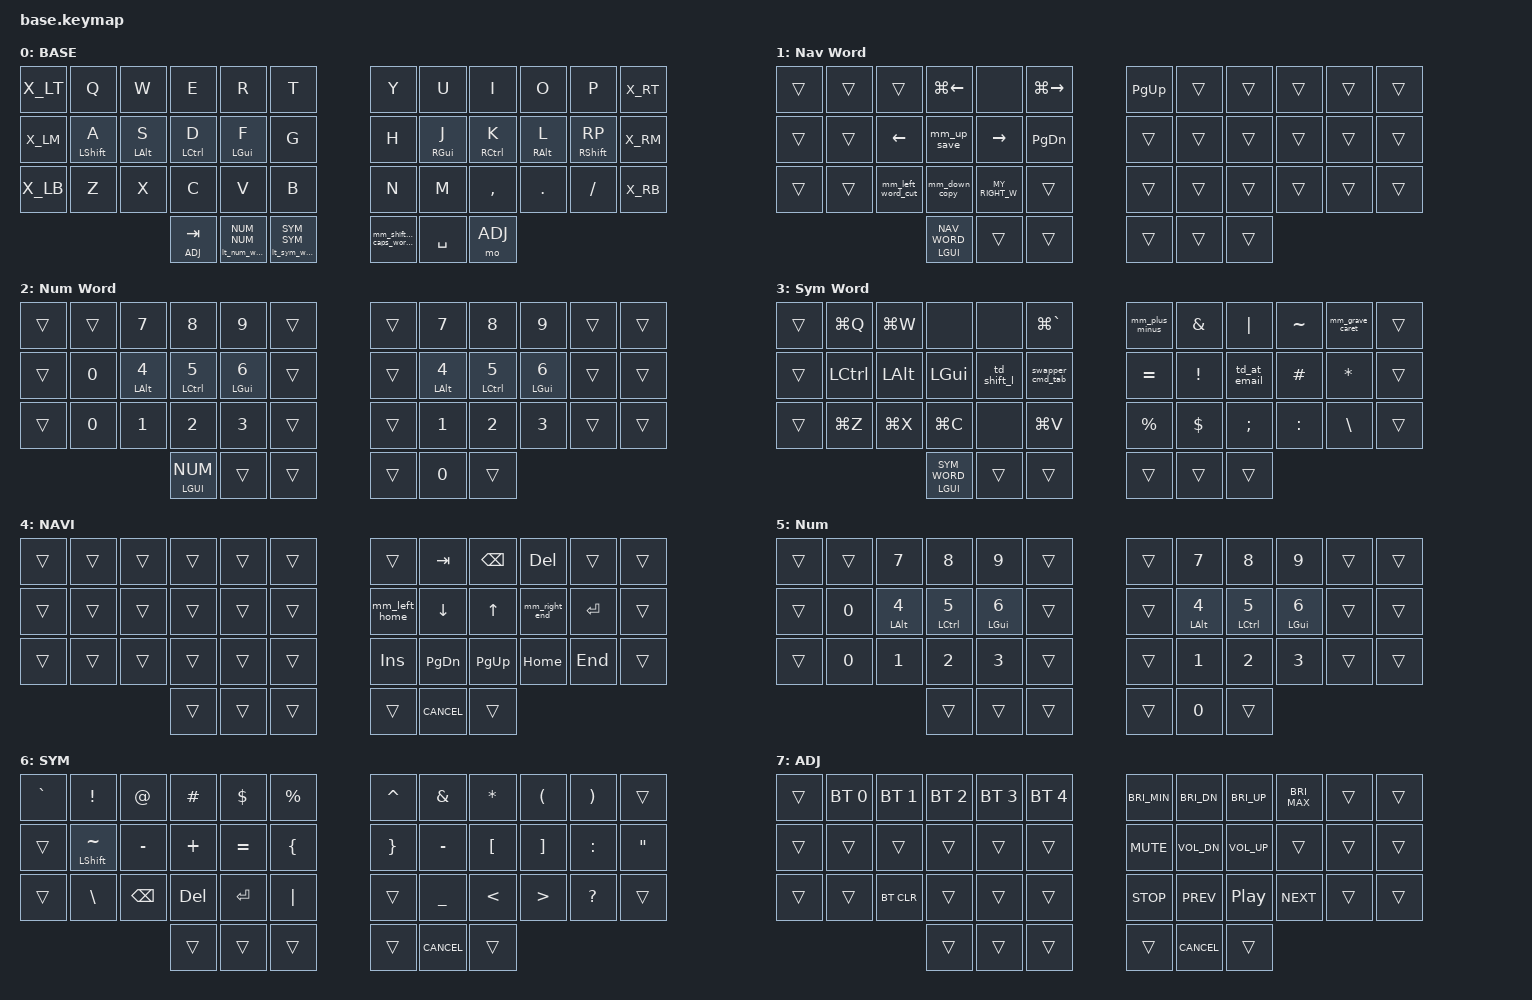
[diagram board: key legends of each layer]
#include <behaviors.dtsi>
#include <behaviors/num_word.dtsi> // requires auto-layer module
#include <dt-bindings/zmk/keys.h>
#include <dt-bindings/zmk/bt.h>
#include <dt-bindings/zmk/outputs.h>

#include "zmk-helpers/helper.h"
#include "extra_keys.h"
#define KEYS_L LT0 LT1 LT2 LT3 LT4 LM0 LM1 LM2 LM3 LM4 LB0 LB1 LB2 LB3 LB4  // left-hand keys
#define KEYS_R RT0 RT1 RT2 RT3 RT4 RM0 RM1 RM2 RM3 RM4 RB0 RB1 RB2 RB3 RB4  // right-hand keys
#ifndef LH2
    #define KEYS_T LH1 LH0 RH0 RH1                                          // thumbs on 34 keys
#else
    #define KEYS_T LH2 LH1 LH0 RH0 RH1 RH2                                  // thumbs on 36+ keys
#endif

#ifndef X_RM
    #define RP SQT  // If no extra col for pinky middle, remap semicolon to sqt
#else
    #define RP SEMICOLON
#endif

#define BASE 0
#define NAV_WORD 1
#define NUM_WORD 2
#define SYM_WORD 3
#define NAV 4
#define NUM 5
#define SYM 6
#define ADJ 7

#define ___ &trans

#define HAS_UROB

#include "includes/custom_keycodes.dtsi"
#include "includes/settings.dtsi"
#include "includes/macros.dtsi"
#include "includes/combos.dtsi"
#include "includes/behaviors_homerow_mods.dtsi"
#include "includes/behaviors_other.dtsi"
#include "includes/behaviors_mod_morph.dtsi"

/ {

    keymap {
      compatible = "zmk,keymap";
      base_layer {
        label= "BASE";
        bindings = <
//╭──────╮ ╭────────────────┬────────────────┬────────────────┬────────────────┬────────────────╮ ╭──────╮ ╭────────────────┬────────────────┬────────────────┬────────────────┬────────────────╮ ╭──────╮
    X_LT     &kp Q            &kp W            &kp E            &kp R            &kp T                       &kp Y            &kp U            &kp I            &kp O            &kp P              X_RT
//├──────┤ ├────────────────┼────────────────┼────────────────┼────────────────┼────────────────┤ ├──────┤ ├────────────────┼────────────────┼────────────────┼────────────────┼────────────────┤ ├──────┤
    X_LM     &hm_l LSHFT A    &hm_l LALT S     &hm_l LCTRL D    &hm_l LGUI F     &kp G                       &kp H            &hm_r RGUI J     &hm_r RCTRL K    &hm_r RALT L     &hm_r RSHFT RP     X_RM
//├──────┤ ├────────────────┼────────────────┼────────────────┼────────────────┼────────────────┤ ├──────┤ ├────────────────┼────────────────┼────────────────┼────────────────┼────────────────┤ ├──────┤
    X_LB     &kp Z            &kp X            &kp C            &kp V            &kp B                       &kp N            &kp M            &kp COMMA        &kp DOT          &kp FSLH           X_RB
//├──────┤ ├────────────────┼────────────────┼────────────────┼────────────────┼────────────────┤ ├──────┤ ├────────────────┼────────────────┼────────────────┼────────────────┼────────────────┤ ├──────┤
                                &ltog ADJ TAB        &lt_num_word NUM NUM       &lt_sym_word SYM SYM      &mm_shift_nav_caps_word_r  &kp SPACE           &mo ADJ
//╰──────╯                    ╰─────────────────────┴─────────────────────┴─────────────────────╯ ╰──────╯ ╰─────────────────────┴─────────────────────┴─────────────────────╯                    ╰──────╯
        >;
      };

      Nav_Word_layer {
        display-name = "Nav Word";
        bindings = <
//╭──────╮ ╭────────────────┬────────────────┬────────────────┬────────────────┬────────────────╮ ╭──────╮ ╭────────────────┬────────────────┬────────────────┬────────────────┬────────────────╮ ╭──────╮
    ___      ___              ___              &kp LG(LEFT)     &none            &kp LG(RIGHT)               &kp PG_UP         ___              ___              ___              ___               ___
//├──────┤ ├────────────────┼────────────────┼────────────────┼────────────────┼────────────────┤ ├──────┤ ├────────────────┼────────────────┼────────────────┼────────────────┼────────────────┤ ├──────┤
    ___      ___              &kp LEFT         &mm_up_save      &kp RIGHT        &kp PG_DN                   ___               ___              ___              ___              ___               ___      
//├──────┤ ├────────────────┼────────────────┼────────────────┼────────────────┼────────────────┤ ├──────┤ ├────────────────┼────────────────┼────────────────┼────────────────┼────────────────┤ ├──────┤
    ___      ___              &mm_left_word_cut &mm_down_copy   &kp MY_RIGHT_W   ___                         ___               ___              ___              ___              ___               ___   
//├──────┤ ├────────────────┼────────────────┼────────────────┼────────────────┼────────────────┤ ├──────┤ ├────────────────┼────────────────┼────────────────┼────────────────┼────────────────┤ ├──────┤
                                &ltog LGUI NAV_WORD   ___                   ___                              ___                   ___                   ___   
//╰──────╯                    ╰─────────────────────┴─────────────────────┴─────────────────────╯ ╰──────╯ ╰─────────────────────┴─────────────────────┴─────────────────────╯                    ╰──────╯
        >;
      };

      Num_Word_layer {
        display-name = "Num Word";
        bindings = <
//╭──────╮ ╭─────────────────┬─────────────────┬─────────────────┬─────────────────┬─────────────────╮ ╭──────╮ ╭─────────────────┬─────────────────┬─────────────────┬─────────────────┬─────────────────╮ ╭──────╮
    ___      ___               &kp N7            &kp N8            &kp N9            ___                          ___               &kp N7            &kp N8            &kp N9            ___                 ___
//├──────┤ ├─────────────────┼─────────────────┼─────────────────┼─────────────────┼─────────────────┤ ├──────┤ ├─────────────────┼─────────────────┼─────────────────┼─────────────────┼─────────────────┤ ├──────┤
    ___      &kp N0            &hm_l LALT N4     &hm_l LCTRL N5    &hm_l LGUI N6     ___                          ___               &hm_r LALT N4     &hm_r LCTRL N5    &hm_r LGUI N6     ___                 ___
//├──────┤ ├─────────────────┼─────────────────┼─────────────────┼─────────────────┼─────────────────┤ ├──────┤ ├─────────────────┼─────────────────┼─────────────────┼─────────────────┼─────────────────┤ ├──────┤
    ___      &kp N0            &kp N1            &kp N2            &kp N3            ___                          ___               &kp N1            &kp N2            &kp N3            ___                 ___   
//├──────┤ ╰─────────────────┴─────────────────┴─────────────────┴─────────────────┼─────────────────┤ ├──────┤ ├─────────────────┼─────────────────┼─────────────────┼─────────────────┴─────────────────╯ ├──────┤
                                     &ltog LGUI NUM           ___                      ___                           ___                      &kp N0                   ___   
//╰──────╯                         ╰─────────────────────┴─────────────────────┴─────────────────────╯ ╰──────╯ ╰─────────────────────┴─────────────────────┴─────────────────────╯                         ╰──────╯
        >;
      };

      Sym_Word_layer {
        display-name = "Sym Word";
        bindings = <
// ╭────────────────────────┬────────────────────────┬────────────────────────┬────────────────────────┬────────────────────────┬────────────────────────╮    ╭────────────────────────┬────────────────────────┬────────────────────────┬────────────────────────┬────────────────────────┬────────────────────────╮
     ___                      &kp LG(Q)                &kp LG(W)                &none                    &none                    &kp LG(GRAVE)                 &mm_plus_minus           &kp AMPERSAND            &kp PIPE                 &kp TILDE                &mm_grave_caret           ___   
// ├────────────────────────┼────────────────────────┼────────────────────────┼────────────────────────┼────────────────────────┼────────────────────────┤    ├────────────────────────┼────────────────────────┼────────────────────────┼────────────────────────┼────────────────────────┼────────────────────────┤
     ___                      &kp LEFT_CONTROL         &kp LEFT_ALT             &kp LEFT_GUI             &td_shift_l              &swapper_cmd_tab              &kp EQUAL                &kp EXCLAMATION          &td_at_email             &kp HASH                 &kp ASTERISK              ___   
// ├────────────────────────┼────────────────────────┼────────────────────────┼────────────────────────┼────────────────────────┼────────────────────────┤    ├────────────────────────┼────────────────────────┼────────────────────────┼────────────────────────┼────────────────────────┼────────────────────────┤
     ___                      &kp LG(Z)                &kp LG(X)                &kp LG(C)                &none                    &kp LG(V)                     &kp PERCENT              &kp DOLLAR               &kp SEMICOLON            &kp COLON                &kp BACKSLASH             ___   
// ╰────────────────────────┴────────────────────────┴────────────────────────┴────────────────────────┼────────────────────────┼────────────────────────┤    ├────────────────────────┼────────────────────────┼────────────────────────┼────────────────────────┴────────────────────────┼────────────────────────╯
                                                                                &ltog LGUI SYM_WORD      ___                      ___                           ___                      ___                      ___   
//                                                                            ╰────────────────────────┴────────────────────────┴────────────────────────╯    ╰────────────────────────┴────────────────────────┴────────────────────────╯
        >;
      };

      nav_layer {
        label= "NAVI";
        bindings = <
//╭──────╮ ╭─────────────┬─────────────┬─────────────┬─────────────┬─────────────╮ ╭──────╮ ╭─────────────┬─────────────┬─────────────┬─────────────┬─────────────╮ ╭──────╮
    ___      ___           ___           ___           ___           ___                      ___           &kp TAB       &kp BSPC      &kp DEL       ___             ___ 
//├──────┤ ├─────────────┼─────────────┼─────────────┼─────────────┼─────────────┤ ├──────┤ ├─────────────┼─────────────┼─────────────┼─────────────┼─────────────┤ ├──────┤
    ___      ___           ___           ___           ___           ___                      &mm_left_home &kp DOWN      &kp UP        &mm_right_end &kp RET         ___ 
//├──────┤ ├─────────────┼─────────────┼─────────────┼─────────────┼─────────────┤ ├──────┤ ├─────────────┼─────────────┼─────────────┼─────────────┼─────────────┤ ├──────┤
    ___      ___           ___           ___           ___           ___                      &kp INS       &kp PG_DN     &kp PG_UP     &kp HOME      &kp END         ___
//├──────┤ ╰─────────────┼─────────────┴─────────────┼─────────────┼─────────────┤ ├──────┤ ├─────────────┼─────────────┼─────────────┴───────────────────────────╯ ├──────┤
                                         ___           ___           ___                      ___           &kp K_CANCEL   ___                 
//╰──────╯                             ╰─────────────┴─────────────┴─────────────╯ ╰──────╯ ╰─────────────┴─────────────┴─────────────╯                             ╰──────╯
        >;
      };


      Num_layer {
        display-name = "Num";
        bindings = <
//╭──────╮ ╭─────────────────┬─────────────────┬─────────────────┬─────────────────┬─────────────────╮ ╭──────╮ ╭─────────────────┬─────────────────┬─────────────────┬─────────────────┬─────────────────╮ ╭──────╮
    ___      ___               &kp N7            &kp N8            &kp N9            ___                          ___               &kp N7            &kp N8            &kp N9            ___                 ___ 
//├──────┤ ├─────────────────┼─────────────────┼─────────────────┼─────────────────┼─────────────────┤ ├──────┤ ├─────────────────┼─────────────────┼─────────────────┼─────────────────┼─────────────────┤ ├──────┤
    ___      &kp N0            &hm_l LALT N4     &hm_l LCTRL N5    &hm_l LGUI N6     ___                          ___               &hm_r LALT N4     &hm_r LCTRL N5    &hm_r LGUI N6     ___                 ___
//├──────┤ ├─────────────────┼─────────────────┼─────────────────┼─────────────────┼─────────────────┤ ├──────┤ ├─────────────────┼─────────────────┼─────────────────┼─────────────────┼─────────────────┤ ├──────┤
    ___      &kp N0            &kp N1            &kp N2            &kp N3            ___                          ___               &kp N1            &kp N2            &kp N3            ___                 ___   
//├──────┤ ╰─────────────────┴─────────────────┴─────────────────┴─────────────────┼─────────────────┤ ├──────┤ ├─────────────────┼─────────────────┼─────────────────┼─────────────────┴─────────────────╯ ├──────┤
                                       ___                    ___                      ___                           ___                      &kp N0                    ___   
//╰──────╯                         ╰─────────────────────┴─────────────────────┴─────────────────────╯ ╰──────╯ ╰─────────────────────┴─────────────────────┴─────────────────────╯                         ╰──────╯
        >;
      };

      sym_layer {
        label= "SYM";
         bindings = <
//╭──────╮ ╭─────────────┬─────────────┬─────────────┬─────────────┬─────────────╮ ╭──────╮ ╭─────────────┬─────────────┬─────────────┬─────────────┬─────────────╮ ╭──────╮
  &kp GRAVE  &kp EXCL      &kp AT        &kp HASH      &kp DLLR      &kp PRCNT                &kp CARET     &kp AMPS      &kp ASTERISK  &kp LPAR      &kp RPAR        ___       
//├──────┤ ├─────────────┼─────────────┼─────────────┼─────────────┼─────────────┤ ├──────┤ ├─────────────┼─────────────┼─────────────┼─────────────┼─────────────┤ ├──────┤
    ___   &hm_l LSHFT TILDE &kp MINUS    &kp PLUS      &kp EQUAL     &kp LBRC                 &kp RBRC      &kp MINUS     &kp LBKT      &kp RBKT      &kp COLON      &kp DQT    
//├──────┤ ├─────────────┼─────────────┼─────────────┼─────────────┼─────────────┤ ├──────┤ ├─────────────┼─────────────┼─────────────┼─────────────┼─────────────┤ ├──────┤
    ___      &kp BSLH      &kp BSPC      &kp DEL       &kp RET       &kp PIPE                 ___           &kp UNDER     &kp LT        &kp GT        &kp QMARK       ___
//├──────┤ ╰─────────────┼─────────────┴─────────────┼─────────────┼─────────────┤ ├──────┤ ├─────────────┼─────────────┼─────────────┴───────────────────────────╯ ├──────┤
                                         ___           ___           ___                      ___           &kp K_CANCEL   ___                 
//╰──────╯                             ╰─────────────┴─────────────┴─────────────╯ ╰──────╯ ╰─────────────┴─────────────┴─────────────╯                             ╰──────╯
        >;
      };

      adj_layer {
        label= "ADJ";
         bindings = <
//╭──────╮ ╭─────────────┬─────────────┬─────────────┬─────────────┬─────────────╮ ╭──────╮ ╭─────────────┬─────────────┬─────────────┬─────────────┬─────────────╮ ╭──────╮
    ___      &bt BT_SEL 0 &bt BT_SEL 1  &bt BT_SEL 2  &bt BT_SEL 3   &bt BT_SEL 4             &kp C_BRI_MIN &kp C_BRI_DN  &kp C_BRI_UP  &kp C_BRI_MAX ___             ___
//├──────┤ ├─────────────┼─────────────┼─────────────┼─────────────┼─────────────┤ ├──────┤ ├─────────────┼─────────────┼─────────────┼─────────────┼─────────────┤ ├──────┤
    ___      ___           ___           ___           ___           ___                      &kp K_MUTE    &kp C_VOL_DN  &kp C_VOL_UP  ___           ___             ___
//├──────┤ ├─────────────┼─────────────┼─────────────┼─────────────┼─────────────┤ ├──────┤ ├─────────────┼─────────────┼─────────────┼─────────────┼─────────────┤ ├──────┤
    ___      ___           &bt BT_CLR    ___           ___           ___                      &kp C_STOP    &kp C_PREV    &kp C_PLAY_PAUSE &kp C_NEXT ___             ___
//├──────┤ ╰─────────────┼─────────────┴─────────────┼─────────────┼─────────────┤ ├──────┤ ├─────────────┼─────────────┼─────────────┴───────────────────────────╯ ├──────┤
                                         ___           ___           ___                      ___           &kp K_CANCEL   ___                 
//╰──────╯                             ╰─────────────┴─────────────┴─────────────╯ ╰──────╯ ╰─────────────┴─────────────┴─────────────╯                             ╰──────╯
        >;
      };
    };
};
